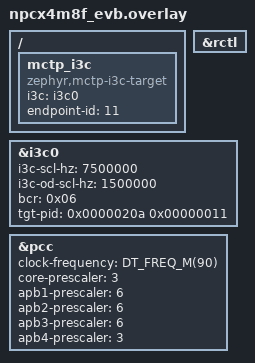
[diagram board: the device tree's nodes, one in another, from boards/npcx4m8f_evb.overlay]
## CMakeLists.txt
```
cmake_minimum_required(VERSION 3.28.0)

find_package(Zephyr REQUIRED HINTS $ENV{ZEPHYR_BASE})
project(mctp_i3c_bus_endpoint)

target_sources(app PRIVATE src/main.c)
```

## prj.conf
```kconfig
CONFIG_I3C=y
CONFIG_MCTP=y
CONFIG_MCTP_I3C_TARGET=y
CONFIG_LOG=y
CONFIG_LOG_BUFFER_SIZE=4096
```

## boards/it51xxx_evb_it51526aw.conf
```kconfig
CONFIG_I3CS_TX_FIFO_4096_BYTE=y
CONFIG_I3CS_RX_FIFO_4096_BYTE=y
CONFIG_I3C_SHELL=y
CONFIG_I3C_TARGET_ROLE_ONLY=y
```

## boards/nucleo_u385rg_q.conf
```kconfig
CONFIG_I3C_LOG_LEVEL_OFF=y
```

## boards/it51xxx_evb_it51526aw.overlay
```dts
/*
 * Copyright (c) 2026 ITE Corporation. All Rights Reserved.
 *
 * SPDX-License-Identifier: Apache-2.0
 */

/ {
	mctp_i3c: mctp_i3c {
		compatible = "zephyr,mctp-i3c-target";
		i3c = <&i3c2>;
		endpoint-id = <11>;
	};
};

&i3c2 {

	pinctrl-0 = <&i3c2_clk_gpe2_default &i3c2_data_gpe3_default>;
	pinctrl-names = "default";

	bcr = <0x06>;
	pid-random-value = <0x00000011>;
	status = "okay";
};
```

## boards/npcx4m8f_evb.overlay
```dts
/*
 * Copyright (c) 2025 Intel Corporation
 *
 * SPDX-License-Identifier: Apache-2.0
 */
&rctl {
	status = "okay";
};

&i3c0 {
	i3c-scl-hz = <7500000>;
	i3c-od-scl-hz = <1500000>;

	bcr = <0x06>;
	tgt-pid = <0x0000020a 0x00000011>;
	status = "okay";
};

&pcc {
	clock-frequency = <DT_FREQ_M(90)>; /* OFMCLK runs at 90MHz */
	core-prescaler = <3>; /* CORE_CLK runs at 30MHz */
	apb1-prescaler = <6>; /* APB1_CLK runs at 15MHz */
	apb2-prescaler = <6>; /* APB2_CLK runs at 15MHz */
	apb3-prescaler = <6>; /* APB3_CLK runs at 15MHz */
	apb4-prescaler = <3>; /* APB4_CLK runs at 30MHz */
};

/ {
	mctp_i3c: mctp_i3c {
		compatible = "zephyr,mctp-i3c-target";
		i3c = <&i3c0>;
		endpoint-id = <11>;
	};
};
```

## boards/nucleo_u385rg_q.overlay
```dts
/*
 * Copyright (c) 2026 Tenstorrent AI ULC
 *
 * SPDX-License-Identifier: Apache-2.0
 */

&i3c1 {
	pinctrl-0 = <&i3c1_scl_pb2 &i3c1_sda_pc1>;
	pinctrl-names = "default";
	i3c-scl-hz = <1000000>;
	i2c-scl-hz = <400000>;
	target-mode;
	mipi-instance = <0x8>;
	status = "okay";
};

/ {
	mctp_i3c: mctp_i3c {
		compatible = "zephyr,mctp-i3c-target";
		i3c = <&i3c1>;
		endpoint-id = <11>;
	};
};
```

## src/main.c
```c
/*
 * Copyright (c) 2025 Intel Corporation
 *
 * SPDX-License-Identifier: Apache-2.0
 */

#include <stdlib.h>
#include <stdio.h>
#include <assert.h>
#include <zephyr/types.h>
#include <zephyr/kernel.h>
#include <libmctp.h>
#include <zephyr/pmci/mctp/mctp_i3c_target.h>

#include <zephyr/logging/log.h>
LOG_MODULE_REGISTER(mctp_i3c_bus_endpoint);

MCTP_I3C_TARGET_DT_DEFINE(mctp_i3c_ctrl, DT_NODELABEL(mctp_i3c));

K_SEM_DEFINE(mctp_rx, 0, 1);

struct mctp *mctp_ctx;

#define BUS_OWNER_ID 20

static void rx_message_handler(struct k_work *work)
{
	ARG_UNUSED(work);

	mctp_message_tx(mctp_ctx, BUS_OWNER_ID, false, 0, "pong", sizeof("pong"));

	k_sem_give(&mctp_rx);
}
K_WORK_DEFINE(rx_message_work, rx_message_handler);

static void rx_message(uint8_t eid, bool tag_owner, uint8_t msg_tag, void *data, void *msg,
		       size_t len)
{
	LOG_INF("received message \"%s\" from endpoint %d, replying with \"pong\"", (char *)msg,
		eid);

	k_work_submit(&rx_message_work);
}

int main(void)
{
	LOG_INF("MCTP Host EID:%d on %s\n", mctp_i3c_ctrl.endpoint_id, CONFIG_BOARD_TARGET);

	mctp_ctx = mctp_init();
	__ASSERT_NO_MSG(mctp_ctx != NULL);
	mctp_register_bus(mctp_ctx, &mctp_i3c_ctrl.binding, mctp_i3c_ctrl.endpoint_id);
	mctp_set_rx_all(mctp_ctx, rx_message, NULL);

	/*
	 * MCTP poll loop, listening for messages.
	 */
	while (true) {
		k_sem_take(&mctp_rx, K_FOREVER);
	}

	return 0;
}
```
